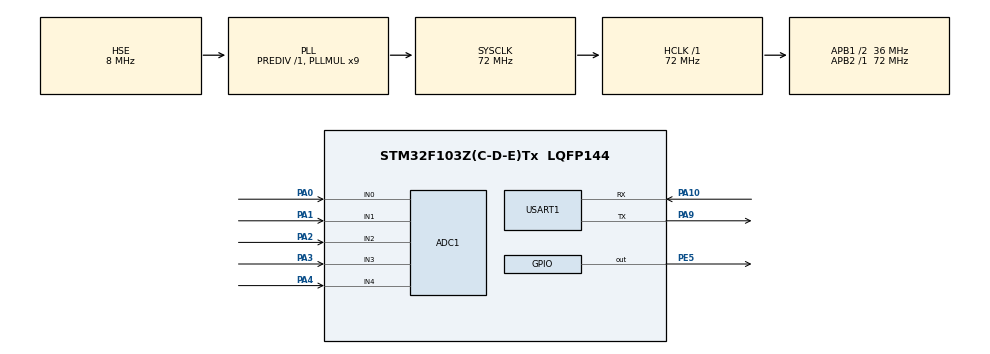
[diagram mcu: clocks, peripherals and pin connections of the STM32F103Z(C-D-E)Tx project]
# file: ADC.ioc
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ADC1.Channel-0\#ChannelRegularConversion=ADC_CHANNEL_0
ADC1.ContinuousConvMode=DISABLE
ADC1.DiscontinuousConvMode=DISABLE
ADC1.NbrOfConversion=1
ADC1.NbrOfConversionFlag=1
ADC1.Rank-0\#ChannelRegularConversion=1
ADC1.SamplingTime-0\#ChannelRegularConversion=ADC_SAMPLETIME_55CYCLES_5
ADC1.master=1
FREERTOS.Tasks01=ADC_Task,0,128,ADC_Function,Default,NULL,Dynamic,NULL,NULL;Init_Task,2,128,Init_Function,Default,NULL,Dynamic,NULL,NULL;LED_Task,-3,128,LED_Function,Default,NULL,Dynamic,NULL,NULL
Mcu.Family=STM32F1
Mcu.Name=STM32F103Z(C-D-E)Tx
Mcu.Package=LQFP144
NVIC.PriorityGroup=NVIC_PRIORITYGROUP_4
NVIC.TIM1_UP_IRQn=true\:15\:0\:false\:false\:true\:false\:false\:true
NVIC.TimeBase=TIM1_UP_IRQn
NVIC.TimeBaseIP=TIM1
OSC_IN.Mode=HSE-External-Oscillator
OSC_IN.Signal=RCC_OSC_IN
OSC_OUT.Mode=HSE-External-Oscillator
OSC_OUT.Signal=RCC_OSC_OUT
PA0-WKUP.Signal=ADCx_IN0
PA1.Signal=ADCx_IN1
PA10.Mode=Asynchronous
PA10.Signal=USART1_RX
PA13.Mode=Serial_Wire
PA13.Signal=SYS_JTMS-SWDIO
PA14.Mode=Serial_Wire
PA14.Signal=SYS_JTCK-SWCLK
PA2.Signal=ADCx_IN2
PA3.Signal=ADCx_IN3
PA4.Signal=ADCx_IN4
PA9.Mode=Asynchronous
PA9.Signal=USART1_TX
PE5.Signal=GPIO_Output
ProjectManager.HeapSize=0x200
ProjectManager.StackSize=0x400
ProjectManager.TargetToolchain=MDK-ARM V5.32
RCC.ADCPresc=RCC_ADCPCLK2_DIV6
RCC.AHBFreq_Value=72000000
RCC.APB1CLKDivider=RCC_HCLK_DIV2
RCC.APB1Freq_Value=36000000
RCC.APB1TimFreq_Value=72000000
RCC.APB2Freq_Value=72000000
RCC.APB2TimFreq_Value=72000000
RCC.HCLKFreq_Value=72000000
RCC.PLLMUL=RCC_PLL_MUL9
RCC.PLLSourceVirtual=RCC_PLLSOURCE_HSE
RCC.SYSCLKFreq_VALUE=72000000
RCC.SYSCLKSource=RCC_SYSCLKSOURCE_PLLCLK
RCC.USBFreq_Value=72000000
SH.ADCx_IN0.0=ADC1_IN0,IN0
SH.ADCx_IN1.0=ADC1_IN1,IN1
SH.ADCx_IN2.0=ADC1_IN2,IN2
SH.ADCx_IN3.0=ADC1_IN3,IN3
SH.ADCx_IN4.0=ADC1_IN4,IN4
USART1.VirtualMode=VM_ASYNC
VP_FREERTOS_VS_CMSIS_V1.Mode=CMSIS_V1
VP_SYS_VS_tim1.Mode=TIM1
board=custom

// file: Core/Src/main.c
/* USER CODE BEGIN Header */
/**
  ******************************************************************************
  * @file           : main.c  本例程ADC代码采用的是多通道单次查询的方式
  * @brief          : Main program body

  ******************************************************************************
  * @attention
  *
  * Copyright (c) 2023 STMicroelectronics.
  * All rights reserved.
  *
  * This software is licensed under terms that can be found in the LICENSE file
  * in the root directory of this software component.
  * If no LICENSE file comes with this software, it is provided AS-IS.
  *
  ******************************************************************************
  */
/* USER CODE END Header */
#include "main.h"
#include "cmsis_os.h"
#include "adc.h"
#include "usart.h"
#include "gpio.h"

void SystemClock_Config(void);
void MX_FREERTOS_Init(void);

int main(void)
{

  /* MCU Configuration--------------------------------------------------------*/

  /* Reset of all peripherals, Initializes the Flash interface and the Systick. */
  HAL_Init();

  /* Configure the system clock */
  SystemClock_Config();

  /* Initialize all configured peripherals */
  MX_GPIO_Init();
  MX_ADC1_Init();
  MX_USART1_UART_Init();

  /* Call init function for freertos objects (in freertos.c) */
  MX_FREERTOS_Init();
  /* Start scheduler */
  osKernelStart();

  /* We should never get here as control is now taken by the scheduler */
  /* Infinite loop */
  while (1)
  {

  }
}

void SystemClock_Config(void)
{
  RCC_OscInitTypeDef RCC_OscInitStruct = {0};
  RCC_ClkInitTypeDef RCC_ClkInitStruct = {0};
  RCC_PeriphCLKInitTypeDef PeriphClkInit = {0};

  /** Initializes the RCC Oscillators according to the specified parameters
  * in the RCC_OscInitTypeDef structure.
  */
  RCC_OscInitStruct.OscillatorType = RCC_OSCILLATORTYPE_HSE;
  RCC_OscInitStruct.HSEState = RCC_HSE_ON;
  RCC_OscInitStruct.HSEPredivValue = RCC_HSE_PREDIV_DIV1;
  RCC_OscInitStruct.HSIState = RCC_HSI_ON;
  RCC_OscInitStruct.PLL.PLLState = RCC_PLL_ON;
  RCC_OscInitStruct.PLL.PLLSource = RCC_PLLSOURCE_HSE;
  RCC_OscInitStruct.PLL.PLLMUL = RCC_PLL_MUL9;
  if (HAL_RCC_OscConfig(&RCC_OscInitStruct) != HAL_OK)
  {
    Error_Handler();
  }
  /** Initializes the CPU, AHB and APB buses clocks
  */
  RCC_ClkInitStruct.ClockType = RCC_CLOCKTYPE_HCLK|RCC_CLOCKTYPE_SYSCLK
                              |RCC_CLOCKTYPE_PCLK1|RCC_CLOCKTYPE_PCLK2;
  RCC_ClkInitStruct.SYSCLKSource = RCC_SYSCLKSOURCE_PLLCLK;
  RCC_ClkInitStruct.AHBCLKDivider = RCC_SYSCLK_DIV1;
  RCC_ClkInitStruct.APB1CLKDivider = RCC_HCLK_DIV2;
  RCC_ClkInitStruct.APB2CLKDivider = RCC_HCLK_DIV1;

  if (HAL_RCC_ClockConfig(&RCC_ClkInitStruct, FLASH_LATENCY_2) != HAL_OK)
  {
    Error_Handler();
  }
  PeriphClkInit.PeriphClockSelection = RCC_PERIPHCLK_ADC;
  PeriphClkInit.AdcClockSelection = RCC_ADCPCLK2_DIV6;
  if (HAL_RCCEx_PeriphCLKConfig(&PeriphClkInit) != HAL_OK)
  {
    Error_Handler();
  }
}

void HAL_TIM_PeriodElapsedCallback(TIM_HandleTypeDef *htim)
{
  if (htim->Instance == TIM1) {
    HAL_IncTick();
  }
}

void Error_Handler(void)
{
  __disable_irq();
  while (1)
  {
  }
}

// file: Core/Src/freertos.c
/* USER CODE BEGIN Header */
/**
  ******************************************************************************
  * File Name          : freertos.c
  * Description        : Code for freertos applications
  ******************************************************************************
  * @attention
  *
  * Copyright (c) 2023 STMicroelectronics.
  * All rights reserved.
  *
  * This software is licensed under terms that can be found in the LICENSE file
  * in the root directory of this software component.
  * If no LICENSE file comes with this software, it is provided AS-IS.
  *
  ******************************************************************************
  */
/* USER CODE END Header */

#include "FreeRTOS.h"
#include "task.h"
#include "main.h"
#include "cmsis_os.h"

/* USER CODE BEGIN PTD */
uint16_t ADC_Value=0,ADC_Volt=0;
uint8_t str_buff[64];
uint8_t adc_mark=0;
/* USER CODE END PTD */

osThreadId ADC_TaskHandle;
osThreadId Init_TaskHandle;
osThreadId LED_TaskHandle;

void ADC_Function(void const * argument);
void Init_Function(void const * argument);
void LED_Function(void const * argument);

void MX_FREERTOS_Init(void); /* (MISRA C 2004 rule 8.1) */

/* GetIdleTaskMemory prototype (linked to static allocation support) */
void vApplicationGetIdleTaskMemory( StaticTask_t **ppxIdleTaskTCBBuffer, StackType_t **ppxIdleTaskStackBuffer, uint32_t *pulIdleTaskStackSize );

/* USER CODE BEGIN GET_IDLE_TASK_MEMORY */
static StaticTask_t xIdleTaskTCBBuffer;
static StackType_t xIdleStack[configMINIMAL_STACK_SIZE];

void vApplicationGetIdleTaskMemory( StaticTask_t **ppxIdleTaskTCBBuffer, StackType_t **ppxIdleTaskStackBuffer, uint32_t *pulIdleTaskStackSize )
{
  *ppxIdleTaskTCBBuffer = &xIdleTaskTCBBuffer;
  *ppxIdleTaskStackBuffer = &xIdleStack[0];
  *pulIdleTaskStackSize = configMINIMAL_STACK_SIZE;
  /* place for user code */
}
/* USER CODE END GET_IDLE_TASK_MEMORY */

void MX_FREERTOS_Init(void) {

  /* Create the thread(s) */
  /* definition and creation of ADC_Task */
  osThreadDef(ADC_Task, ADC_Function, osPriorityNormal, 0, 256);
  ADC_TaskHandle = osThreadCreate(osThread(ADC_Task), NULL);

  /* definition and creation of Init_Task */
  osThreadDef(Init_Task, Init_Function, osPriorityHigh, 0, 128);
  Init_TaskHandle = osThreadCreate(osThread(Init_Task), NULL);

  /* definition and creation of LED_Task */
  osThreadDef(LED_Task, LED_Function, osPriorityIdle, 0, 128);
  LED_TaskHandle = osThreadCreate(osThread(LED_Task), NULL);

}

void ADC_Function(void const * argument)
{
	uint16_t angle_get;										//角度值保存
  uint16_t volage_get;										//电压值保存
  /* USER CODE BEGIN ADC_Function */
  /* Infinite loop */
  for(;;)
  {
		HAL_Delay(500);
		volage_get = ADC_Get_Average(1);							//读取电压值
		volage_get = volage_get*3.3*100/4096;					//转换电压，扩大100倍
		angle_get = ADC_Get_Average(0);					        //读取ADC值
		my_printf(1,"电压值（A1）：%d.%d,采样值（A0):%d\r\n",volage_get/100,volage_get%100,angle_get);

  }
  /* USER CODE END ADC_Function */
}

void Init_Function(void const * argument)
{
  /* USER CODE BEGIN Init_Function */
  /* Infinite loop */
  for(;;)
  {
		taskENTER_CRITICAL(); //进入临界区
		vTaskDelete(NULL);

		HAL_ADCEx_Calibration_Start(&hadc1);					//校准ADC1

    osDelay(1);
		taskEXIT_CRITICAL();            //退出临界区

  }
  /* USER CODE END Init_Function */
}

void LED_Function(void const * argument)
{
  /* USER CODE BEGIN LED_Function */
//	osThreadSuspend(LED_TaskHandle);
  /* Infinite loop */
  for(;;)
  {

		HAL_GPIO_TogglePin(GPIOE,GPIO_PIN_5);
		HAL_Delay(600);
  }
  /* USER CODE END LED_Function */
}
